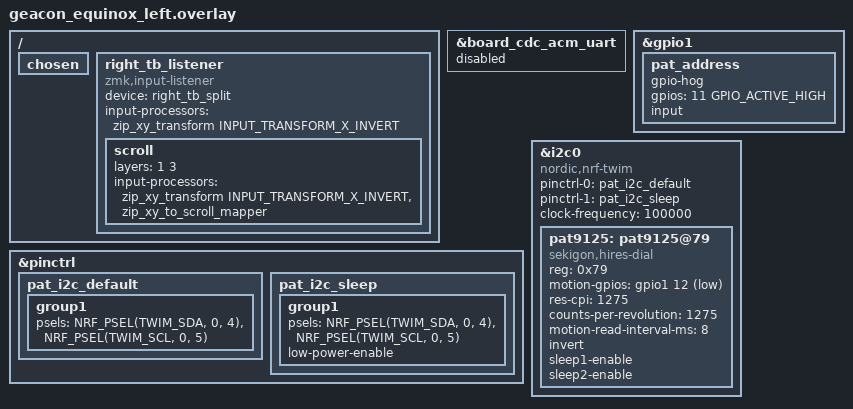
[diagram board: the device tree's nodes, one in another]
#include "GeaconEquinox.dtsi"
#define EQUINOX_HAS_DIAL 1
/ {
    chosen {
        /delete-property/ zephyr,uart-mcumgr;
        /delete-property/ zephyr,bt-mon-uart;
        /delete-property/ zephyr,bt-c2h-uart;
    };
    right_tb_listener {
        compatible = "zmk,input-listener";
        device = <&right_tb_split>;
        /* Previous Y inversion + PCB rotation by 180 degrees = X inversion. */
        input-processors = <&zip_xy_transform INPUT_TRANSFORM_X_INVERT>;
        scroll {
            layers = <1 3>;
            input-processors = <&zip_xy_transform INPUT_TRANSFORM_X_INVERT>,
                               <&zip_xy_to_scroll_mapper>;
        };
    };
};
/* Two HID interfaces + Studio/debug CDC need six IN endpoints, not eight. */
&board_cdc_acm_uart { status = "disabled"; };
&gpio1 {
    pat_address {
        gpio-hog;
        /* Keep ID_SEL high impedance from reset through operation.
         * The sensor selects 0x79 before the MCU can drive this pin. */
        gpios = <11 GPIO_ACTIVE_HIGH>;
        input;
    };
};
&pinctrl {
    pat_i2c_default: pat_i2c_default {
        group1 { psels = <NRF_PSEL(TWIM_SDA, 0, 4)>, <NRF_PSEL(TWIM_SCL, 0, 5)>; };
    };
    pat_i2c_sleep: pat_i2c_sleep {
        group1 {
            psels = <NRF_PSEL(TWIM_SDA, 0, 4)>, <NRF_PSEL(TWIM_SCL, 0, 5)>;
            low-power-enable;
        };
    };
};
&i2c0 {
    status = "okay";
    compatible = "nordic,nrf-twim";
    pinctrl-0 = <&pat_i2c_default>;
    pinctrl-1 = <&pat_i2c_sleep>;
    pinctrl-names = "default", "sleep";
    clock-frequency = <100000>;
    pat9125: pat9125@79 {
        compatible = "sekigon,hires-dial";
        reg = <0x79>;
        motion-gpios = <&gpio1 12 (GPIO_ACTIVE_LOW | GPIO_PULL_UP)>;
        res-cpi = <1275>;
        /* Initial upstream reference value; calibrate against the physical dial. */
        counts-per-revolution = <1275>;
        motion-read-interval-ms = <8>;
        invert;
        sleep1-enable;
        sleep2-enable;
    };
};
